# STM32C562 register map
File version: 2.1.0
CPU: CM33 r0p4, little endian, MPU, FPU, 4 interrupt priority bits
Registers are 32-bit, read-write, reset 0x0 unless marked. A register's access mark holds for its fields unless they carry their own. Offsets are from the block's base; [hi:lo] are bit positions; {n}, {i} and the like mark numbered series.

## COMP1 — COMP address block description
Base 0x40004000
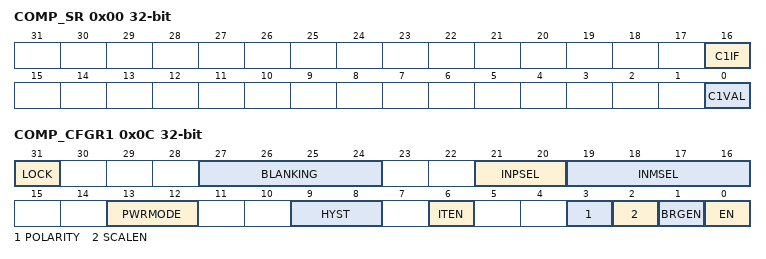
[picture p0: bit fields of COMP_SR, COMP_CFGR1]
0x00 COMP_SR ro — Comparator status register
  [16] C1IF — COMP1 Channel interrupt flag
  [0] C1VAL — COMP1 Channel output status bit
0x04 COMP_ICFR — Comparator interrupt clear flag register
  [16] CC1IF — Clear COMP Channel1 interrupt flag
0x0C COMP_CFGR1 — Comparator configuration register 1
  [31] LOCK
    0=COMP_CFGR1[31:0] register is read/write; 1=COMP_CFGR1[31:0] and COMP_OR registers are read-only
  [27:24] BLANKING — COMP Channel blanking source selection
    0=No blanking; {v}=comp_blk{v} (v=1..6)
  [21:20] INPSEL — COMP non-inverting input selection
  [19:16] INMSEL — COMP Channel inverting input selection
  [13:12] PWRMODE — Power mode of the COMP Channel
    0=High speed / full power; 1=Medium speed / medium power
  [9:8] HYST — COMP Channel hysteresis selection
    0=No hysteresis; 1=Low hysteresis; 2=Medium hysteresis; 3=High hysteresis
  [6] ITEN — COMP Channel interrupt enable
    0=Interrupt generation disabled for COMP Channel; 1=Interrupt generation enabled for COMP Channel
  [3] POLARITY — COMP Channel polarity selection
    0=COMP Channel output is not inverted; 1=COMP Channel output is inverted
  [2] SCALEN — Voltage scaler enable
    0=Vless thansub>REFINTless than/sub> scaler disabled; 1=Vless thansub>REFINTless than/sub> scaler enabled
  [1] BRGEN — Scaler bridge enable
    0=Scaler resistor bridge disabled; 1=Scaler resistor bridge enabled
  [0] EN — COMP Channel enable
    0=Disable; 1=Enable

## CRC — Cyclic redundancy check calculation unit
Base 0x40023000
0x00 CRC_DR reset 0xFFFFFFFF — CRC data register
  [31:0] DR — Data register bits This register is used to write new data to the CRC calculator. It holds the previous CRC calculation result when it is read. If the data size is less than 32 bits, the least significant bits are used to write/read the correct value.
0x04 CRC_IDR — CRC independent data register
  [31:0] IDR — General-purpose 32-bit data register bits These bits can be used as a temporary storage location for four bytes. This register is not affected by CRC resets generated by the RESET bit in the CRC_CR register
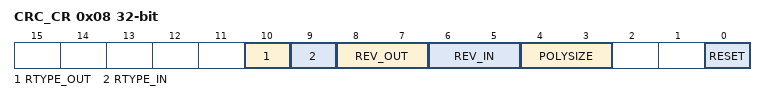
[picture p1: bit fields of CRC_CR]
0x08 CRC_CR — CRC control register
  [10] RTYPE_OUT — Reverse type output This bit controls the reversal granularity of the output data.
    0=Bit level output; 1=Byte or half-word level output
  [9] RTYPE_IN — Reverse type input This bit controls the reversal granularity of the input data.
    0=Bit level input; 1=Byte or half-word level input
  [8:7] REV_OUT — Reverse output data This bit controls the reversal of the bit order of the output data.
    0=Bit order not affected; 1=Bit-reversed output format
  [6:5] REV_IN — Reverse input data These bits control the reversal of the bit order of the input data
    0=Bit order not affected; 1=Bit reversal done by byte; 2=Bit reversal done by half-word; 3=Bit reversal done by word
  [4:3] POLYSIZE — Polynomial size These bits control the size of the polynomial.
    0=32 bit polynomial; 1=16 bit polynomial; 2=8 bit polynomial; 3=7 bit polynomial
  [0] RESET — RESET bit This bit is set by software to reset the CRC calculation unit and set the data register to the value stored in the CRC_INIT register. This bit can only be set, it is automatically cleared by hardware
0x10 CRC_INIT reset 0xFFFFFFFF — CRC initial value
  [31:0] CRC_INIT — Programmable initial CRC value This register is used to write the CRC initial value.
0x14 CRC_POL reset 0x4C11DB7 — CRC polynomial
  [31:0] POL — Programmable polynomial This register is used to write the coefficients of the polynomial to be used for CRC calculation. If the polynomial size is less than 32 bits, the least significant bits have to be used to program the correct value.

## Notices in the file
Copyright (c) 2026 STMicroelectronics.
SPDX-License-Identifier: Apache-2.0
Licensed under the Apache License, Version 2.0 (the "License");
you may not use this file except in compliance with the License.
You may obtain a copy of the License at
http://www.apache.org/licenses/LICENSE-2.0
Unless required by applicable law or agreed to in writing, software
distributed under the License is distributed on an "AS IS" BASIS,
WITHOUT WARRANTIES OR CONDITIONS OF ANY KIND, either express or implied.
See the License for the specific language governing permissions and
limitations under the License.
